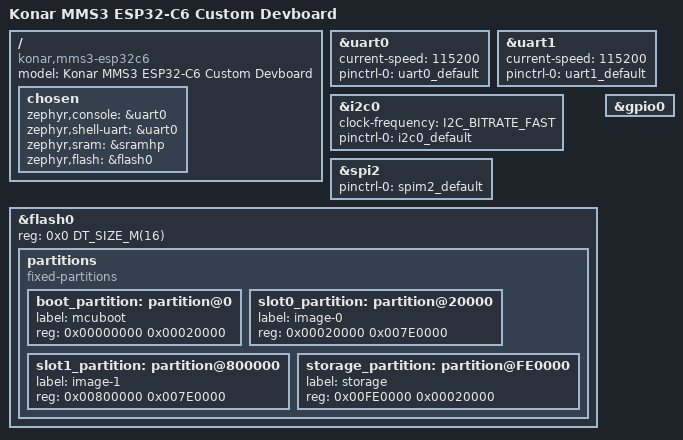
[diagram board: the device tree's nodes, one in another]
/dts-v1/;
#include <espressif/esp32c6/esp32c6.dtsi>
#include "konar_mms3_esp32c6-pinctrl.dtsi"

/ {
	model = "Konar MMS3 ESP32-C6 Custom Devboard";
	compatible = "konar,mms3-esp32c6";

	chosen {
		zephyr,console = &uart0;
		zephyr,shell-uart = &uart0;
		zephyr,sram = &sramhp;
		zephyr,flash = &flash0;
	};
};

&uart0 {
	current-speed = <115200>;
	pinctrl-0 = <&uart0_default>;
	pinctrl-names = "default";
	status = "okay";
};
&uart1 {
	current-speed = <115200>;
	pinctrl-0 = <&uart1_default>;
	pinctrl-names = "default";
	status = "okay";
};

&i2c0 {
	clock-frequency = <I2C_BITRATE_FAST>;
	pinctrl-0 = <&i2c0_default>;
	pinctrl-names = "default";
	status = "okay";
};

&spi2 {
	#address-cells = <1>;
	#size-cells = <0>;
	pinctrl-0 = <&spim2_default>;
	pinctrl-names = "default";
	status = "okay";
};

&flash0 {
    reg = <0x0 DT_SIZE_M(16)>;
    ranges = <0x0 0x0 DT_SIZE_M(16)>;

    partitions {
        compatible = "fixed-partitions";
        #address-cells = <1>;
        #size-cells = <1>;

        boot_partition: partition@0 {
            label = "mcuboot";
            reg = <0x00000000 0x00020000>; /* 128 KB */
        };

        slot0_partition: partition@20000 {
            label = "image-0";
            reg = <0x00020000 0x007E0000>; /* ~7.8 MB primary slot */
        };

        slot1_partition: partition@800000 {
            label = "image-1";
            reg = <0x00800000 0x007E0000>; /* ~7.8 MB secondary (OTA) slot */
        };

        storage_partition: partition@FE0000 {
            label = "storage";
            reg = <0x00FE0000 0x00020000>; /* 128 KB LittleFS / NVS */
        };
    };
};

&gpio0 {
	status = "okay";
};
